# RK3399-AP register map
File version: 1
CPU: CA7 r0p1, little endian, MPU, FPU, I-cache, D-cache, VTOR, 4 interrupt priority bits, 0 interrupts
Registers are 32-bit, read-write, reset 0x0 unless marked. A register's access mark holds for its fields unless they carry their own. Offsets are from the block's base; [hi:lo] are bit positions.

## PMUCRU
Base 0xFF750000
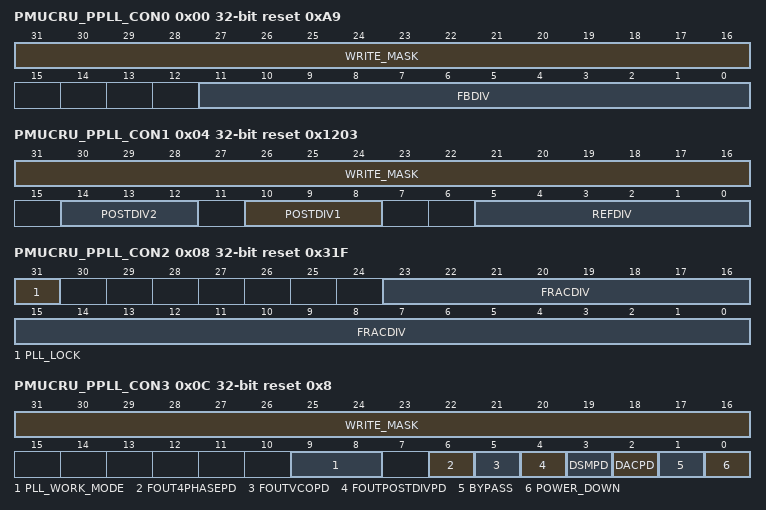
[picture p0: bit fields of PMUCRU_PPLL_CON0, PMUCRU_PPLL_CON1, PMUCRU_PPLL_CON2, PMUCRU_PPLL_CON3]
0x00 PMUCRU_PPLL_CON0 access per field reset 0xA9 — PPLL configuration register0
  [31:16] WRITE_MASK wo — write mask bits When every bit HIGH, enable the writing corresponding bit When every bit LOW, don\'t care the writing corresponding bit
  [11:0] FBDIV rw — Feedback Divide Value Valid divider settings are: [16, 3200] in integer mode [20, 320] in fractional mode Tips: no plus one operation
0x04 PMUCRU_PPLL_CON1 access per field reset 0x1203 — PPLL configuration register1
  [31:16] WRITE_MASK wo — write mask bits When every bit HIGH, enable the writing corresponding bit When every bit LOW, don\'t care the writing corresponding bit
  [14:12] POSTDIV2 rw — Second Post Divide Value (1-7)
  [10:8] POSTDIV1 rw — First Post Divide Value (1-7)
  [5:0] REFDIV rw — Reference Clock Divide Value (1-63)
0x08 PMUCRU_PPLL_CON2 access per field reset 0x31F — PPLL configuration register2
  [31] PLL_LOCK ro — PLL lock status 1\'b0: unlock 1\'b1: lock
  [23:0] FRACDIV rw — Fractional part of feedback divide (fraction = FRAC/2^24)
0x0C PMUCRU_PPLL_CON3 access per field reset 0x8 — PPLL configuration register3
  [31:16] WRITE_MASK wo — write mask bits When every bit HIGH, enable the writing corresponding bit When every bit LOW, don\'t care the writing corresponding bit
  [9:8] PLL_WORK_MODE rw — PLL work mode select 2\'b00: Slow mode, clock from external 24MHz/26MHz OSC (default) 2\'b01: Normal mode, clock from PLL output 2\'b10: Deep slow mode, clock from external 32.768kHz
  [6] FOUT4PHASEPD rw — Power down 4-phase clocks and 2X, 3X, 4X clocks 1\'b0: no power down 1\'b1: power down
  [5] FOUTVCOPD rw — Power down buffered VCO clock 1\'b0: no power down 1\'b1: power down
  [4] FOUTPOSTDIVPD rw — Power down all outputs except for buffered VCO clock 1\'b0: no power down 1\'b1: power down
  [3] DSMPD rw — PLL saturation behavior enable 1\'b0: no power down 1\'b1: power down DSMPD = 1\'b1 ( modulator is disabled, "integer mode")
  [2] DACPD rw — Power down quantization noise cancellation DAC 1\'b0: no power down 1\'b1: power down
  [1] BYPASS rw — PLL Bypass. FREF bypasses PLL to FOUTPOSTDIV 1\'b0: no bypass 1\'b1: bypass
  [0] POWER_DOWN rw — Global power down 1\'b0: no power down 1\'b1: power down
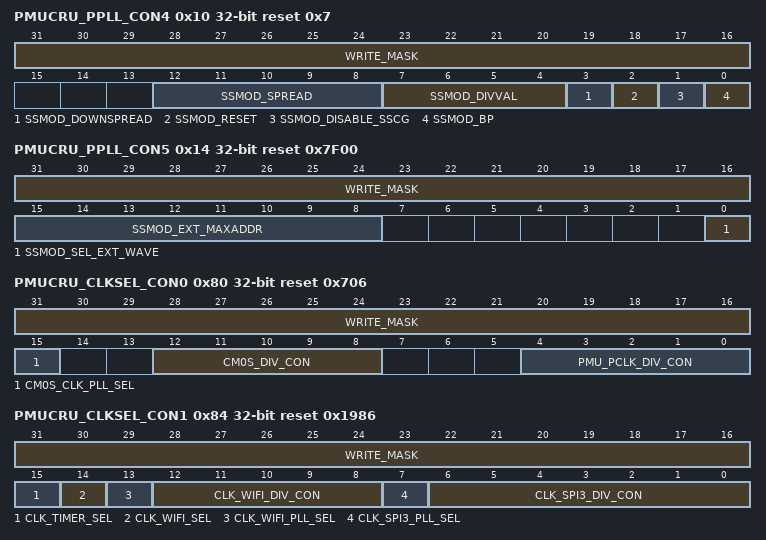
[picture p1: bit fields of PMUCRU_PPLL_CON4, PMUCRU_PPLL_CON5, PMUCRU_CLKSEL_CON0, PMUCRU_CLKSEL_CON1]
0x10 PMUCRU_PPLL_CON4 access per field reset 0x7 — PPLL configuration register4
  [31:16] WRITE_MASK wo — write mask bits When every bit HIGH, enable the writing corresponding bit When every bit LOW, don\'t care the writing corresponding bit
  [12:8] SSMOD_SPREAD rw — spread amplitude % = 0.1 * SPREAD[4:0]
  [7:4] SSMOD_DIVVAL rw — Divider required to set the modulation frequency Divider required to set the modulation frequency
  [3] SSMOD_DOWNSPREAD rw — Selects center spread or downs pread 1\'b0: center spread 1\'b1: down spread
  [2] SSMOD_RESET rw — Reset modulator state 1\'b0: no reset 1\'b1: reset
  [1] SSMOD_DISABLE_SSCG rw — Bypass SSMOD by module 1\'b0: no bypass 1\'b1: bypass
  [0] SSMOD_BP rw — Bypass SSMOD by integration 1\'b0: no bypass 1\'b1: bypass
0x14 PMUCRU_PPLL_CON5 access per field reset 0x7F00 — PPLL configuration register5
  [31:16] WRITE_MASK wo — write mask bits When every bit HIGH, enable the writing corresponding bit When every bit LOW, don\'t care the writing corresponding bit
  [15:8] SSMOD_EXT_MAXADDR rw — External wave table data inputs (0-255)
  [0] SSMOD_SEL_EXT_WAVE rw — select external wave 1\'b0: no select ext_wave 1\'b1: select ext_wave
0x80 PMUCRU_CLKSEL_CON0 access per field reset 0x706 — Internal clock select and divide register0
  [31:16] WRITE_MASK wo — write mask bits When every bit HIGH, enable the writing corresponding bit When every bit LOW, don\'t care the writing corresponding bit
  [15] CM0S_CLK_PLL_SEL rw — cm0s_clk divider control register 1\'b0:PPLL 1\'b1:xin_24m
  [12:8] CM0S_DIV_CON rw — cm0s clock source select control register clk=clk_src/(div_con+1)
  [4:0] PMU_PCLK_DIV_CON rw — pmu_pclk divider control register clk=clk_src/(div_con+1)
0x84 PMUCRU_CLKSEL_CON1 access per field reset 0x1986 — Internal clock select and divide register1
  [31:16] WRITE_MASK wo — write mask bits When every bit HIGH, enable the writing corresponding bit When every bit LOW, don\'t care the writing corresponding bit
  [15] CLK_TIMER_SEL rw — clk_timer source select control register 1\'b0:xin_24m 1\'b1:clk_32k
  [14] CLK_WIFI_SEL rw — clk_wifi source select control register 1\'b0:clk_wifi_divout 1\'b1:clk_wifi_frac
  [13] CLK_WIFI_PLL_SEL rw — clk_wifi_pll source select control register 1\'b0:PPLL 1\'b1:xin_24m
  [12:8] CLK_WIFI_DIV_CON rw — clk_wifi divider control register clk=clk_src/(div_con+1)
  [7] CLK_SPI3_PLL_SEL rw — clk_spi3_pll source select control register 1\'b0:xin_24m 1\'b1:PPLL
  [6:0] CLK_SPI3_DIV_CON rw — clk_spi3 divider control register clk=clk_src/(div_con+1)
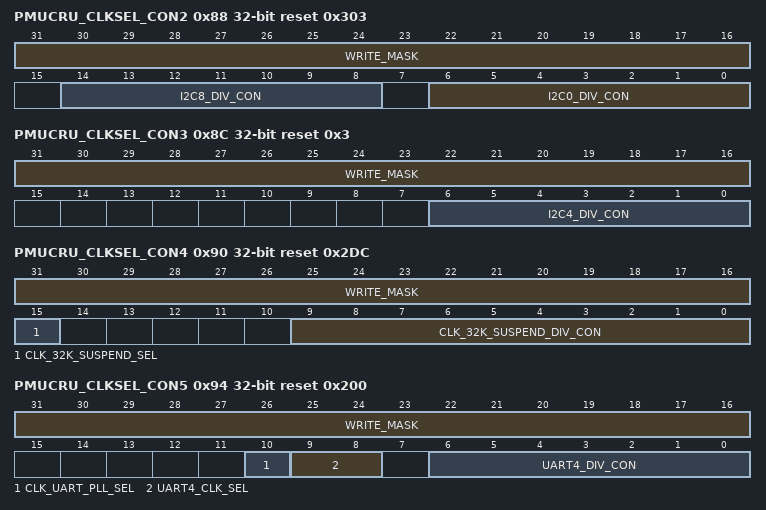
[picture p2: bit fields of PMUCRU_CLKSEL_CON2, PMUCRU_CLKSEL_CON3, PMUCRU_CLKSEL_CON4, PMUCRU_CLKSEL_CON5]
0x88 PMUCRU_CLKSEL_CON2 access per field reset 0x303 — Internal clock select and divide register2
  [31:16] WRITE_MASK wo — write mask bits When every bit HIGH, enable the writing corresponding bit When every bit LOW, don\'t care the writing corresponding bit
  [14:8] I2C8_DIV_CON rw — i2c8 divider control register clk=clk_src/(div_con+1)
  [6:0] I2C0_DIV_CON rw — i2c0 divider control register clk=clk_src/(div_con+1)
0x8C PMUCRU_CLKSEL_CON3 access per field reset 0x3 — Internal clock select and divide register3
  [31:16] WRITE_MASK wo — write mask bits When every bit HIGH, enable the writing corresponding bit When every bit LOW, don\'t care the writing corresponding bit
  [6:0] I2C4_DIV_CON rw — i2c4 divider control register clk=clk_src/(div_con+1)
0x90 PMUCRU_CLKSEL_CON4 access per field reset 0x2DC — Internal clock select and divide register4
  [31:16] WRITE_MASK wo — write mask bits When every bit HIGH, enable the writing corresponding bit When every bit LOW, don\'t care the writing corresponding bit
  [15] CLK_32K_SUSPEND_SEL rw — clk_32k_suspend source select control register 1\'b0:test clock out 1\'b1:32k from pmu 24m div
  [9:0] CLK_32K_SUSPEND_DIV_CON rw — clk_32k_suspend divider control register clk=clk_src/(div_con+1)
0x94 PMUCRU_CLKSEL_CON5 access per field reset 0x200 — Internal clock select and divide register5
  [31:16] WRITE_MASK wo — write mask bits When every bit HIGH, enable the writing corresponding bit When every bit LOW, don\'t care the writing corresponding bit
  [10] CLK_UART_PLL_SEL rw — clk_uart_pll source select control register 1\'b0:xin_24m 1\'b1:PPLL
  [9:8] UART4_CLK_SEL rw — uart4_clk source select control register 2\'b00:clk_uart4_divout 2\'b01:clk_uart4_frac 2\'b10:xin_24m
  [6:0] UART4_DIV_CON rw — uart4 divider control register clk=clk_src/(div_con+1)
0x98 PMUCRU_CLKFRAC_CON0 reset 0xBB8EA60 — Internal clock select and divide register6
  [31:0] UART4_FRAC_DIV_CON — uart4_frac divider control register Fout = Fsrc*numerator/denominator High 16-bit for numerator Low 16-bit for denominator
0x9C PMUCRU_CLKFRAC_CON1 reset 0xBB8EA60 — Internal clock select and divide register7
  [31:0] WIFI_FRAC_DIV_CON — wifi_frac divider control register Fout = Fsrc*numerator/denominator High 16-bit for numerator Low 16-bit for denominator
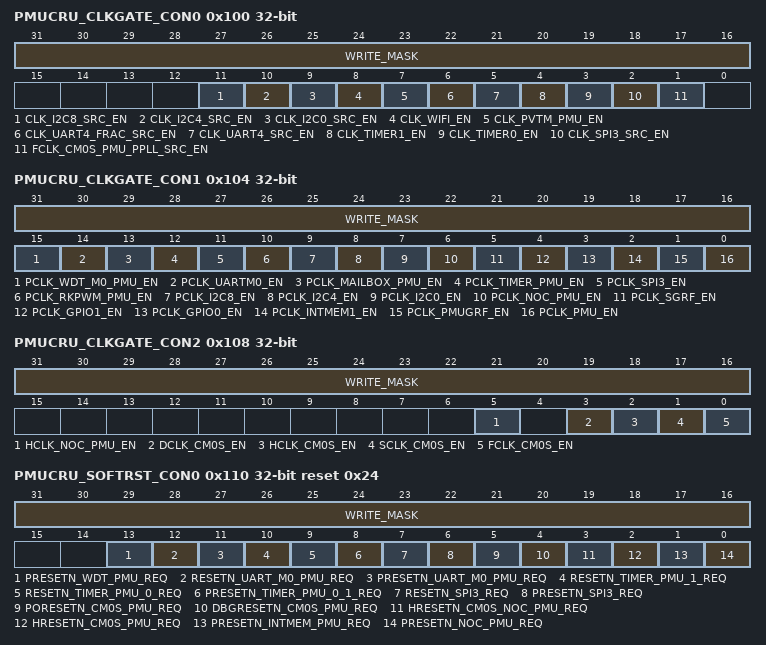
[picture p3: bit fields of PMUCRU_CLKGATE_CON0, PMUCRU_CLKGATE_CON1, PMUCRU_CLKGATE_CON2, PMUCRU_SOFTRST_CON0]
0x100 PMUCRU_CLKGATE_CON0 access per field — Internal clock gating register0
  [31:16] WRITE_MASK wo — write mask bits When every bit HIGH, enable the writing corresponding bit When every bit LOW, don\'t care the writing corresponding bit
  [11] CLK_I2C8_SRC_EN rw — clk_i2c8_src clock disable bit When HIGH, disable clock
  [10] CLK_I2C4_SRC_EN rw — clk_i2c4_src clock disable bit When HIGH, disable clock
  [9] CLK_I2C0_SRC_EN rw — clk_i2c0_src clock disable bit When HIGH, disable clock
  [8] CLK_WIFI_EN rw — clk_wifi clock disable bit When HIGH, disable clock
  [7] CLK_PVTM_PMU_EN rw — clk_pvtm_pmu clock disable bit When HIGH, disable clock
  [6] CLK_UART4_FRAC_SRC_EN rw — clk_uart4_frac_src clock disable bit When HIGH, disable clock
  [5] CLK_UART4_SRC_EN rw — clk_uart4_src clock disable bit When HIGH, disable clock
  [4] CLK_TIMER1_EN rw — clk_timer1 clock disable bit When HIGH, disable clock
  [3] CLK_TIMER0_EN rw — clk_timer0 clock disable bit When HIGH, disable clock
  [2] CLK_SPI3_SRC_EN rw — clk_spi3_src clock disable bit When HIGH, disable clock
  [1] FCLK_CM0S_PMU_PPLL_SRC_EN rw — fclk_cm0s_pmu_ppll_src clock disable bit When HIGH, disable clock
0x104 PMUCRU_CLKGATE_CON1 access per field — Internal clock gating register1
  [31:16] WRITE_MASK wo — write mask bits When every bit HIGH, enable the writing corresponding bit When every bit LOW, don\'t care the writing corresponding bit
  [15] PCLK_WDT_M0_PMU_EN rw — pclk_wdt_m0_pmu clock disable bit When HIGH, disable clock
  [14] PCLK_UARTM0_EN rw — pclk_uartm0 clock disable bit When HIGH, disable clock
  [13] PCLK_MAILBOX_PMU_EN rw — pclk_mailbox_pmu clock disable bit When HIGH, disable clock
  [12] PCLK_TIMER_PMU_EN rw — pclk_timer_pmu clock disable bit When HIGH, disable clock
  [11] PCLK_SPI3_EN rw — pclk_spi3 clock disable bit When HIGH, disable clock
  [10] PCLK_RKPWM_PMU_EN rw — pclk_rkpwm_pmu clock disable bit When HIGH, disable clock
  [9] PCLK_I2C8_EN rw — pclk_i2c8 clock disable bit When HIGH, disable clock
  [8] PCLK_I2C4_EN rw — pclk_i2c4 clock disable bit When HIGH, disable clock
  [7] PCLK_I2C0_EN rw — pclk_i2c0 clock disable bit When HIGH, disable clock
  [6] PCLK_NOC_PMU_EN rw — pclk_noc_pmu clock disable bit When HIGH, disable clock Suggest always on
  [5] PCLK_SGRF_EN rw — pclk_sgrf clock disable bit When HIGH, disable clock Suggest always on
  [4] PCLK_GPIO1_EN rw — pclk_gpio1 clock disable bit When HIGH, disable clock
  [3] PCLK_GPIO0_EN rw — pclk_gpio0 clock disable bit When HIGH, disable clock
  [2] PCLK_INTMEM1_EN rw — pclk_intmem1 clock disable bit When HIGH, disable clock
  [1] PCLK_PMUGRF_EN rw — pclk_pmugrf clock disable bit When HIGH, disable clock Suggest always on
  [0] PCLK_PMU_EN rw — pclk_pmu clock disable bit When HIGH, disable clock
0x108 PMUCRU_CLKGATE_CON2 access per field — Internal clock gating register2
  [31:16] WRITE_MASK wo — write mask bits When every bit HIGH, enable the writing corresponding bit When every bit LOW, don\'t care the writing corresponding bit
  [5] HCLK_NOC_PMU_EN rw — hclk_noc_pmu clock disable bit When HIGH, disable clock Suggest always on
  [3] DCLK_CM0S_EN rw — dclk_cm0s clock disable bit When HIGH, disable clock
  [2] HCLK_CM0S_EN rw — hclk_cm0s clock disable bit When HIGH, disable clock
  [1] SCLK_CM0S_EN rw — sclk_cm0s clock disable bit When HIGH, disable clock
  [0] FCLK_CM0S_EN rw — fclk_cm0s clock disable bit When HIGH, disable clock
0x110 PMUCRU_SOFTRST_CON0 access per field reset 0x24 — Internal software reset control register0
  [31:16] WRITE_MASK wo — write mask bits When every bit HIGH, enable the writing corresponding bit When every bit LOW, don\'t care the writing corresponding bit
  [13] PRESETN_WDT_PMU_REQ rw — presetn_wdt_pmu request bit When HIGH, reset relative logic
  [12] RESETN_UART_M0_PMU_REQ rw — resetn_uart_m0_pmu request bit When HIGH, reset relative logic
  [11] PRESETN_UART_M0_PMU_REQ rw — presetn_uart_m0_pmu request bit When HIGH, reset relative logic
  [10] RESETN_TIMER_PMU_1_REQ rw — resetn_timer_pmu_1 request bit When HIGH, reset relative logic
  [9] RESETN_TIMER_PMU_0_REQ rw — resetn_timer_pmu_0 request bit When HIGH, reset relative logic
  [8] PRESETN_TIMER_PMU_0_1_REQ rw — presetn_timer_pmu_0_1 request bit When HIGH, reset relative logic
  [7] RESETN_SPI3_REQ rw — resetn_spi3 request bit When HIGH, reset relative logic
  [6] PRESETN_SPI3_REQ rw — presetn_spi3 request bit When HIGH, reset relative logic
  [5] PORESETN_CM0S_PMU_REQ rw — poresetn_cm0s_pmu request bit When HIGH, reset relative logic
  [4] DBGRESETN_CM0S_PMU_REQ rw — dbgresetn_cm0s_pmu request bit When HIGH, reset relative logic
  [3] HRESETN_CM0S_NOC_PMU_REQ rw — hresetn_cm0s_noc_pmu request bit When HIGH, reset relative logic
  [2] HRESETN_CM0S_PMU_REQ rw — hresetn_cm0s_pmu request bit When HIGH, reset relative logic
  [1] PRESETN_INTMEM_PMU_REQ rw — presetn_intmem_pmu request bit When HIGH, reset relative logic
  [0] PRESETN_NOC_PMU_REQ rw — presetn_noc_pmu request bit When HIGH, reset relative logic
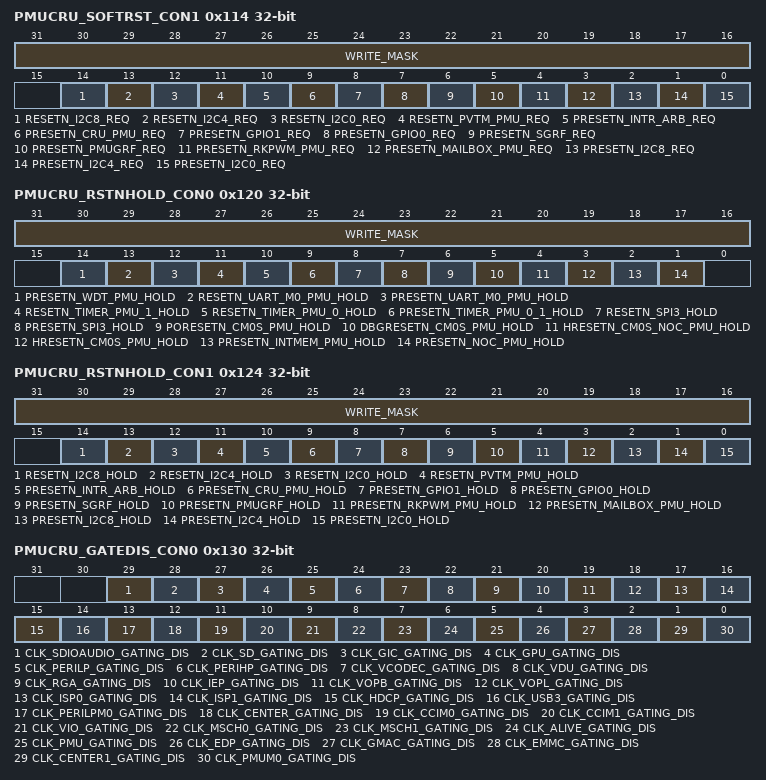
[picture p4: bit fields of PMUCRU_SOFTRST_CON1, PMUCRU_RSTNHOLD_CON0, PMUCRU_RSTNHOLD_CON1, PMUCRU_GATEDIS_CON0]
0x114 PMUCRU_SOFTRST_CON1 access per field — Internal software reset control register1
  [31:16] WRITE_MASK wo — write mask bits When every bit HIGH, enable the writing corresponding bit When every bit LOW, don\'t care the writing corresponding bit
  [14] RESETN_I2C8_REQ rw — resetn_i2c8 request bit When HIGH, reset relative logic
  [13] RESETN_I2C4_REQ rw — resetn_i2c4 request bit When HIGH, reset relative logic
  [12] RESETN_I2C0_REQ rw — resetn_i2c0 request bit When HIGH, reset relative logic
  [11] RESETN_PVTM_PMU_REQ rw — resetn_pvtm_pmu request bit When HIGH, reset relative logic
  [10] PRESETN_INTR_ARB_REQ rw — presetn_intr_arb request bit When HIGH, reset relative logic
  [9] PRESETN_CRU_PMU_REQ rw — presetn_cru_pmu request bit When HIGH, reset relative logic
  [8] PRESETN_GPIO1_REQ rw — presetn_gpio1 request bit When HIGH, reset relative logic
  [7] PRESETN_GPIO0_REQ rw — presetn_gpio0 request bit When HIGH, reset relative logic
  [6] PRESETN_SGRF_REQ rw — presetn_sgrf request bit When HIGH, reset relative logic
  [5] PRESETN_PMUGRF_REQ rw — presetn_pmugrf request bit When HIGH, reset relative logic
  [4] PRESETN_RKPWM_PMU_REQ rw — presetn_rkpwm_pmu request bit When HIGH, reset relative logic
  [3] PRESETN_MAILBOX_PMU_REQ rw — presetn_mailbox_pmu request bit When HIGH, reset relative logic
  [2] PRESETN_I2C8_REQ rw — presetn_i2c8 request bit When HIGH, reset relative logic
  [1] PRESETN_I2C4_REQ rw — presetn_i2c4 request bit When HIGH, reset relative logic
  [0] PRESETN_I2C0_REQ rw — presetn_i2c0 request bit When HIGH, reset relative logic
0x120 PMUCRU_RSTNHOLD_CON0 access per field — Internal reset hold control register0
  [31:16] WRITE_MASK wo — write mask bits When every bit HIGH, enable the writing corresponding bit When every bit LOW, don\'t care the writing corresponding bit
  [14] PRESETN_WDT_PMU_HOLD rw — presetn_wdt_pmu_hold control bit When HIGH, reset hold, can\'t be reset by any reset source
  [13] RESETN_UART_M0_PMU_HOLD rw — resetn_uart_m0_pmu_hold control bit When HIGH, reset hold, can\'t be reset by any reset source
  [12] PRESETN_UART_M0_PMU_HOLD rw — presetn_uart_m0_pmu_hold control bit When HIGH, reset hold, can\'t be reset by any reset source
  [11] RESETN_TIMER_PMU_1_HOLD rw — resetn_timer_pmu_1_hold control bit When HIGH, reset hold, can\'t be reset by any reset source
  [10] RESETN_TIMER_PMU_0_HOLD rw — resetn_timer_pmu_0_hold control bit When HIGH, reset hold, can\'t be reset by any reset source
  [9] PRESETN_TIMER_PMU_0_1_HOLD rw — presetn_timer_pmu_0_1_hold control bit When HIGH, reset hold, can\'t be reset by any reset source
  [8] RESETN_SPI3_HOLD rw — resetn_spi3_hold control bit When HIGH, reset hold, can\'t be reset by any reset source
  [7] PRESETN_SPI3_HOLD rw — presetn_spi3_hold control bit When HIGH, reset hold, can\'t be reset by any reset source
  [6] PORESETN_CM0S_PMU_HOLD rw — poresetn_cm0s_pmu_hold control bit When HIGH, reset hold, can\'t be reset by any reset source
  [5] DBGRESETN_CM0S_PMU_HOLD rw — dbgresetn_cm0s_pmu_hold control bit When HIGH, reset hold, can\'t be reset by any reset source
  [4] HRESETN_CM0S_NOC_PMU_HOLD rw — hresetn_cm0s_noc_pmu_hold control bit When HIGH, reset hold, can\'t be reset by any reset source
  [3] HRESETN_CM0S_PMU_HOLD rw — hresetn_cm0s_pmu_hold control bit When HIGH, reset hold, can\'t be reset by any reset source
  [2] PRESETN_INTMEM_PMU_HOLD rw — presetn_intmem_pmu_hold control bit When HIGH, reset hold, can\'t be reset by any reset source
  [1] PRESETN_NOC_PMU_HOLD rw — presetn_noc_pmu_hold control bit When HIGH, reset hold, can\'t be reset by any reset source
0x124 PMUCRU_RSTNHOLD_CON1 access per field — Internal reset hold control register1
  [31:16] WRITE_MASK wo — write mask bits When every bit HIGH, enable the writing corresponding bit When every bit LOW, don\'t care the writing corresponding bit
  [14] RESETN_I2C8_HOLD rw — resetn_i2c8_hold control bit When HIGH, reset hold, can\'t be reset by any reset source
  [13] RESETN_I2C4_HOLD rw — resetn_i2c4_hold control bit When HIGH, reset hold, can\'t be reset by any reset source
  [12] RESETN_I2C0_HOLD rw — resetn_i2c0_hold control bit When HIGH, reset hold, can\'t be reset by any reset source
  [11] RESETN_PVTM_PMU_HOLD rw — resetn_pvtm_pmu_hold control bit When HIGH, reset hold, can\'t be reset by any reset source
  [10] PRESETN_INTR_ARB_HOLD rw — presetn_intr_arb_hold control bit When HIGH, reset hold, can\'t be reset by any reset source
  [9] PRESETN_CRU_PMU_HOLD rw — presetn_cru_pmu_hold control bit When HIGH, reset hold, can\'t be reset by any reset source
  [8] PRESETN_GPIO1_HOLD rw — presetn_gpio1_hold control bit When HIGH, reset hold, can\'t be reset by any reset source
  [7] PRESETN_GPIO0_HOLD rw — presetn_gpio0_hold control bit When HIGH, reset hold, can\'t be reset by any reset source
  [6] PRESETN_SGRF_HOLD rw — presetn_sgrf_hold control bit When HIGH, reset hold, can\'t be reset by any reset source
  [5] PRESETN_PMUGRF_HOLD rw — presetn_pmugrf_hold control bit When HIGH, reset hold, can\'t be reset by any reset source
  [4] PRESETN_RKPWM_PMU_HOLD rw — presetn_rkpwm_pmu_hold control bit When HIGH, reset hold, can\'t be reset by any reset source
  [3] PRESETN_MAILBOX_PMU_HOLD rw — presetn_mailbox_pmu_hold control bit When HIGH, reset hold, can\'t be reset by any reset source
  [2] PRESETN_I2C8_HOLD rw — presetn_i2c8_hold control bit When HIGH, reset hold, can\'t be reset by any reset source
  [1] PRESETN_I2C4_HOLD rw — presetn_i2c4_hold control bit When HIGH, reset hold, can\'t be reset by any reset source
  [0] PRESETN_I2C0_HOLD rw — presetn_i2c0_hold control bit When HIGH, reset hold, can\'t be reset by any reset source
0x130 PMUCRU_GATEDIS_CON0 — Internal gate disable control register0
  [29] CLK_SDIOAUDIO_GATING_DIS — clk_sdioaudio gate disable bit When HIGH, gate disable, open all clocks power domain idle request needed
  [28] CLK_SD_GATING_DIS — clk_sd gate disable bit When HIGH, gate disable, open all clocks power domain idle request needed
  [27] CLK_GIC_GATING_DIS — clk_gic gate disable bit When HIGH, gate disable, open all clocks power domain idle request needed
  [26] CLK_GPU_GATING_DIS — clk_gpu gate disable bit When HIGH, gate disable, open all clocks power domain idle request needed
  [25] CLK_PERILP_GATING_DIS — clk_perilp gate disable bit When HIGH, gate disable, open all clocks power domain idle request needed
  [24] CLK_PERIHP_GATING_DIS — clk_perihp gate disable bit When HIGH, gate disable, open all clocks power domain idle request needed
  [23] CLK_VCODEC_GATING_DIS — clk_vcodec gate disable bit When HIGH, gate disable, open all clocks power domain idle request needed
  [22] CLK_VDU_GATING_DIS — clk_vdu gate disable bit When HIGH, gate disable, open all clocks power domain idle request needed
  [21] CLK_RGA_GATING_DIS — clk_rga gate disable bit When HIGH, gate disable, open all clocks power domain idle request needed
  [20] CLK_IEP_GATING_DIS — clk_iep gate disable bit When HIGH, gate disable, open all clocks power domain idle request needed
  [19] CLK_VOPB_GATING_DIS — clk_vopb gate disable bit When HIGH, gate disable, open all clocks power domain idle request needed
  [18] CLK_VOPL_GATING_DIS — clk_vopl gate disable bit When HIGH, gate disable, open all clocks power domain idle request needed
  [17] CLK_ISP0_GATING_DIS — clk_isp0 gate disable bit When HIGH, gate disable, open all clocks power domain idle request needed
  [16] CLK_ISP1_GATING_DIS — clk_isp1 gate disable bit When HIGH, gate disable, open all clocks power domain idle request needed
  [15] CLK_HDCP_GATING_DIS — clk_hdcp gate disable bit When HIGH, gate disable, open all clocks power domain idle request needed
  [14] CLK_USB3_GATING_DIS — clk_usb3 gate disable bit When HIGH, gate disable, open all clocks power domain idle request needed
  [13] CLK_PERILPM0_GATING_DIS — clk_perilpm0 gate disable bit When HIGH, gate disable, open all clocks power domain idle request needed
  [12] CLK_CENTER_GATING_DIS — clk_center gate disable bit When HIGH, gate disable, open all clocks power domain idle request needed
  [11] CLK_CCIM0_GATING_DIS — clk_ccim0 gate disable bit When HIGH, gate disable, open all clocks power domain idle request needed
  [10] CLK_CCIM1_GATING_DIS — clk_ccim1 gate disable bit When HIGH, gate disable, open all clocks power domain idle request needed
  [9] CLK_VIO_GATING_DIS — clk_vio gate disable bit When HIGH, gate disable, open all clocks power domain idle request needed
  [8] CLK_MSCH0_GATING_DIS — clk_msch0 gate disable bit When HIGH, gate disable, open all clocks power domain idle request needed
  [7] CLK_MSCH1_GATING_DIS — clk_msch1 gate disable bit When HIGH, gate disable, open all clocks power domain idle request needed
  [6] CLK_ALIVE_GATING_DIS — clk_alive gate disable bit When HIGH, gate disable, open all clocks power domain idle request needed
  [5] CLK_PMU_GATING_DIS — clk_pmu gate disable bit When HIGH, gate disable, open all clocks power domain idle request needed
  [4] CLK_EDP_GATING_DIS — clk_edp gate disable bit When HIGH, gate disable, open all clocks power domain idle request needed
  [3] CLK_GMAC_GATING_DIS — clk_gmac gate disable bit When HIGH, gate disable, open all clocks power domain idle request needed
  [2] CLK_EMMC_GATING_DIS — clk_emmc gate disable bit When HIGH, gate disable, open all clocks power domain idle request needed
  [1] CLK_CENTER1_GATING_DIS — clk_center1 gate disable bit When HIGH, gate disable, open all clocks power domain idle request needed
  [0] CLK_PMUM0_GATING_DIS — clk_pmum0 gate disable bit When HIGH, gate disable, open all clocks power domain idle request needed
